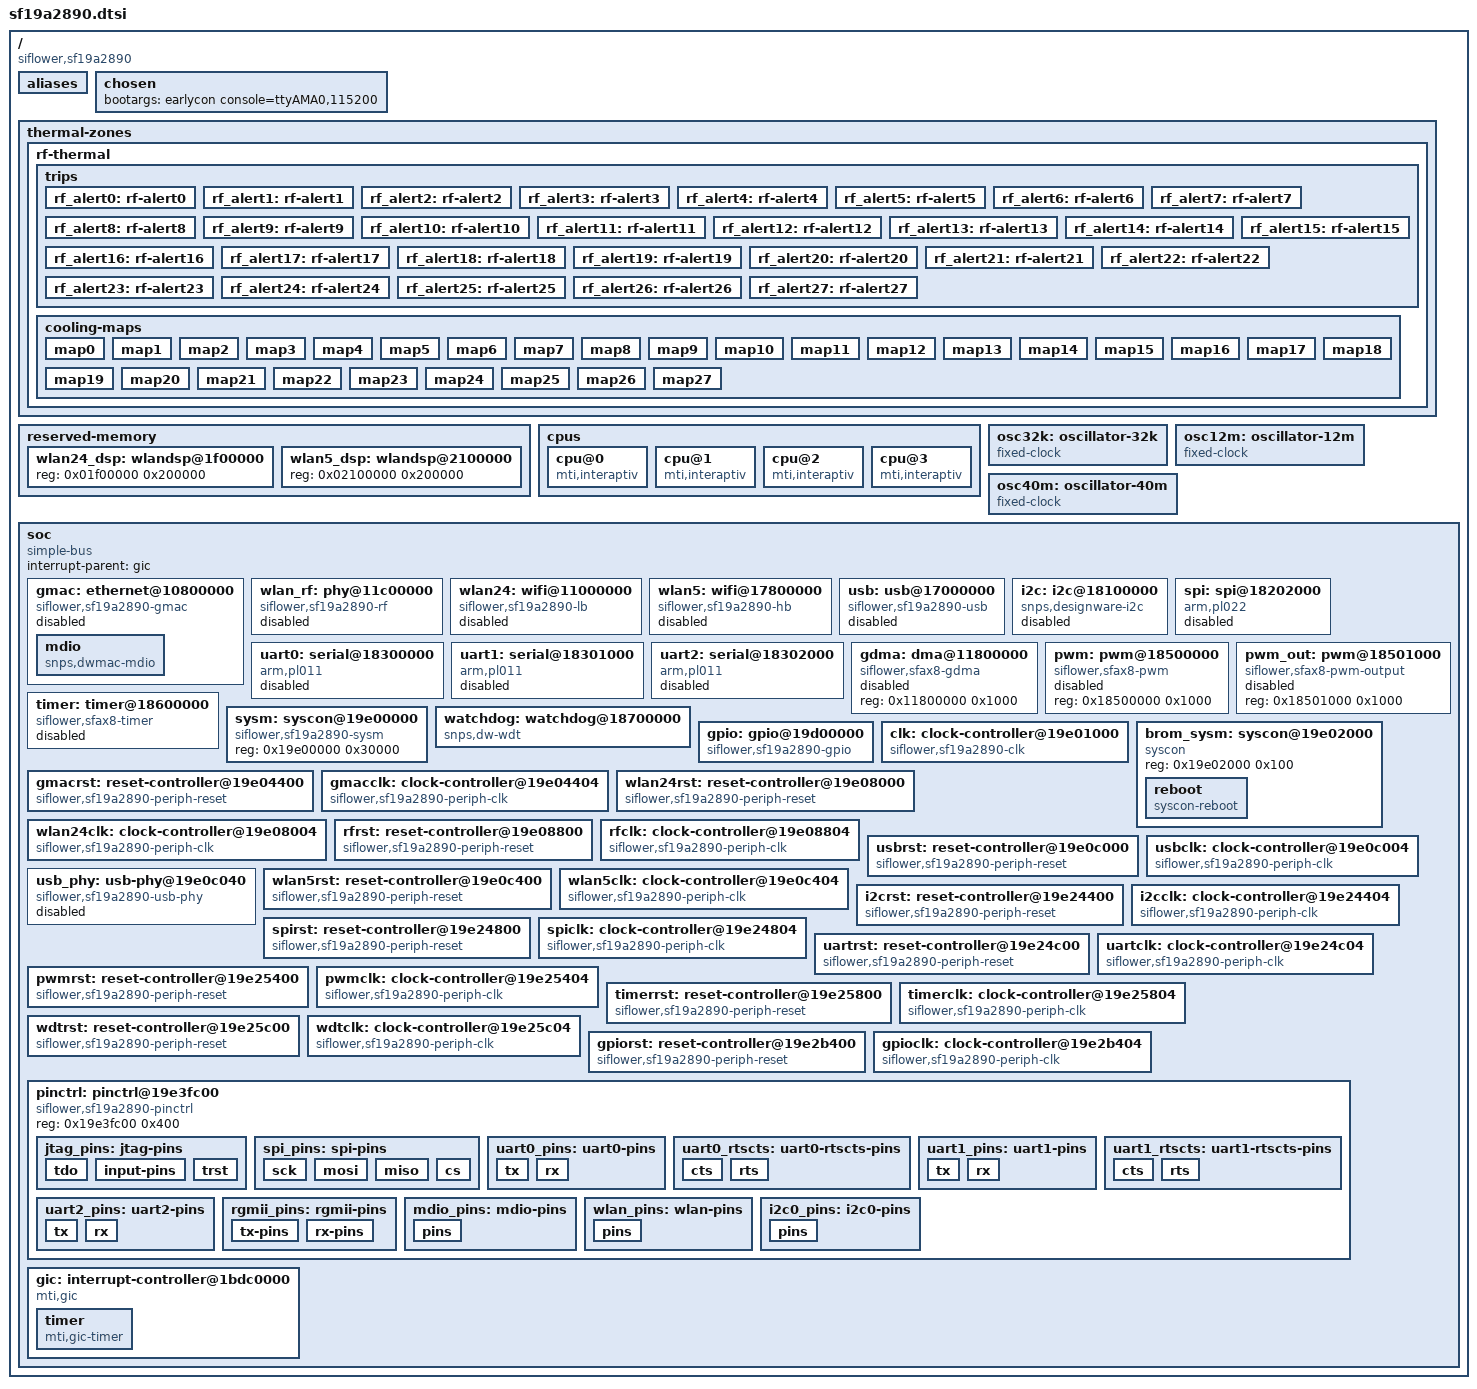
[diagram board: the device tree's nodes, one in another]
#include <dt-bindings/clock/siflower,sf19a2890-clk.h>
#include <dt-bindings/gpio/gpio.h>
#include <dt-bindings/interrupt-controller/irq.h>
#include <dt-bindings/interrupt-controller/mips-gic.h>

/ {
	compatible = "siflower,sf19a2890";
	#address-cells = <1>;
	#size-cells = <1>;


	aliases {
		serial0 = &uart0;
		serial1 = &uart1;
		serial2 = &uart2;
	};

	chosen {
		/*
		 * The vendor u-boot appends "console=ttyS0,115200n8" (and
		 * mem=/rdinit=) via MIPS_CMDLINE_DTB_EXTEND. A console=
		 * argument disables stdout-path based console selection,
		 * and ttyS0 does not exist (the UART is a PL011), which
		 * would leave the kernel silent after earlycon. Name the
		 * real console explicitly so it stays registered.
		 */
		bootargs = "earlycon console=ttyAMA0,115200";
	};

	thermal-zones {
		/*
		 * Mirrors the stock firmware rf_zone: the WiFi RF block is
		 * both the temperature sensor and the cooling device (TX
		 * power reduction), with 28 passive trips from -20C to 115C
		 * in 5C steps and the cooling state equal to the trip index.
		 */
		rf-thermal {
			polling-delay-passive = <1000>;
			polling-delay = <5000>;
			thermal-sensors = <&wlan_rf>;

			trips {
				rf_alert0: rf-alert0 {
					temperature = <(-20000)>;
					hysteresis = <1000>;
					type = "passive";
				};

				rf_alert1: rf-alert1 {
					temperature = <(-15000)>;
					hysteresis = <1000>;
					type = "passive";
				};

				rf_alert2: rf-alert2 {
					temperature = <(-10000)>;
					hysteresis = <1000>;
					type = "passive";
				};

				rf_alert3: rf-alert3 {
					temperature = <(-5000)>;
					hysteresis = <1000>;
					type = "passive";
				};

				rf_alert4: rf-alert4 {
					temperature = <0>;
					hysteresis = <1000>;
					type = "passive";
				};

				rf_alert5: rf-alert5 {
					temperature = <5000>;
					hysteresis = <1000>;
					type = "passive";
				};

				rf_alert6: rf-alert6 {
					temperature = <10000>;
					hysteresis = <1000>;
					type = "passive";
				};

				rf_alert7: rf-alert7 {
					temperature = <15000>;
					hysteresis = <1000>;
					type = "passive";
				};

				rf_alert8: rf-alert8 {
					temperature = <20000>;
					hysteresis = <1000>;
					type = "passive";
				};

				rf_alert9: rf-alert9 {
					temperature = <25000>;
					hysteresis = <1000>;
					type = "passive";
				};

				rf_alert10: rf-alert10 {
					temperature = <30000>;
					hysteresis = <1000>;
					type = "passive";
				};

				rf_alert11: rf-alert11 {
					temperature = <35000>;
					hysteresis = <1000>;
					type = "passive";
				};

				rf_alert12: rf-alert12 {
					temperature = <40000>;
					hysteresis = <1000>;
					type = "passive";
				};

				rf_alert13: rf-alert13 {
					temperature = <45000>;
					hysteresis = <1000>;
					type = "passive";
				};

				rf_alert14: rf-alert14 {
					temperature = <50000>;
					hysteresis = <1000>;
					type = "passive";
				};

				rf_alert15: rf-alert15 {
					temperature = <55000>;
					hysteresis = <1000>;
					type = "passive";
				};

				rf_alert16: rf-alert16 {
					temperature = <60000>;
					hysteresis = <1000>;
					type = "passive";
				};

				rf_alert17: rf-alert17 {
					temperature = <65000>;
					hysteresis = <1000>;
					type = "passive";
				};

				rf_alert18: rf-alert18 {
					temperature = <70000>;
					hysteresis = <1000>;
					type = "passive";
				};

				rf_alert19: rf-alert19 {
					temperature = <75000>;
					hysteresis = <1000>;
					type = "passive";
				};

				rf_alert20: rf-alert20 {
					temperature = <80000>;
					hysteresis = <1000>;
					type = "passive";
				};

				rf_alert21: rf-alert21 {
					temperature = <85000>;
					hysteresis = <1000>;
					type = "passive";
				};

				rf_alert22: rf-alert22 {
					temperature = <90000>;
					hysteresis = <1000>;
					type = "passive";
				};

				rf_alert23: rf-alert23 {
					temperature = <95000>;
					hysteresis = <1000>;
					type = "passive";
				};

				rf_alert24: rf-alert24 {
					temperature = <100000>;
					hysteresis = <1000>;
					type = "passive";
				};

				rf_alert25: rf-alert25 {
					temperature = <105000>;
					hysteresis = <1000>;
					type = "passive";
				};

				rf_alert26: rf-alert26 {
					temperature = <110000>;
					hysteresis = <1000>;
					type = "passive";
				};

				rf_alert27: rf-alert27 {
					temperature = <115000>;
					hysteresis = <1000>;
					type = "passive";
				};
			};

			cooling-maps {
				map0 {
					trip = <&rf_alert0>;
					cooling-device = <&wlan_rf 0 0>;
				};

				map1 {
					trip = <&rf_alert1>;
					cooling-device = <&wlan_rf 1 1>;
				};

				map2 {
					trip = <&rf_alert2>;
					cooling-device = <&wlan_rf 2 2>;
				};

				map3 {
					trip = <&rf_alert3>;
					cooling-device = <&wlan_rf 3 3>;
				};

				map4 {
					trip = <&rf_alert4>;
					cooling-device = <&wlan_rf 4 4>;
				};

				map5 {
					trip = <&rf_alert5>;
					cooling-device = <&wlan_rf 5 5>;
				};

				map6 {
					trip = <&rf_alert6>;
					cooling-device = <&wlan_rf 6 6>;
				};

				map7 {
					trip = <&rf_alert7>;
					cooling-device = <&wlan_rf 7 7>;
				};

				map8 {
					trip = <&rf_alert8>;
					cooling-device = <&wlan_rf 8 8>;
				};

				map9 {
					trip = <&rf_alert9>;
					cooling-device = <&wlan_rf 9 9>;
				};

				map10 {
					trip = <&rf_alert10>;
					cooling-device = <&wlan_rf 10 10>;
				};

				map11 {
					trip = <&rf_alert11>;
					cooling-device = <&wlan_rf 11 11>;
				};

				map12 {
					trip = <&rf_alert12>;
					cooling-device = <&wlan_rf 12 12>;
				};

				map13 {
					trip = <&rf_alert13>;
					cooling-device = <&wlan_rf 13 13>;
				};

				map14 {
					trip = <&rf_alert14>;
					cooling-device = <&wlan_rf 14 14>;
				};

				map15 {
					trip = <&rf_alert15>;
					cooling-device = <&wlan_rf 15 15>;
				};

				map16 {
					trip = <&rf_alert16>;
					cooling-device = <&wlan_rf 16 16>;
				};

				map17 {
					trip = <&rf_alert17>;
					cooling-device = <&wlan_rf 17 17>;
				};

				map18 {
					trip = <&rf_alert18>;
					cooling-device = <&wlan_rf 18 18>;
				};

				map19 {
					trip = <&rf_alert19>;
					cooling-device = <&wlan_rf 19 19>;
				};

				map20 {
					trip = <&rf_alert20>;
					cooling-device = <&wlan_rf 20 20>;
				};

				map21 {
					trip = <&rf_alert21>;
					cooling-device = <&wlan_rf 21 21>;
				};

				map22 {
					trip = <&rf_alert22>;
					cooling-device = <&wlan_rf 22 22>;
				};

				map23 {
					trip = <&rf_alert23>;
					cooling-device = <&wlan_rf 23 23>;
				};

				map24 {
					trip = <&rf_alert24>;
					cooling-device = <&wlan_rf 24 24>;
				};

				map25 {
					trip = <&rf_alert25>;
					cooling-device = <&wlan_rf 25 25>;
				};

				map26 {
					trip = <&rf_alert26>;
					cooling-device = <&wlan_rf 26 26>;
				};

				map27 {
					trip = <&rf_alert27>;
					cooling-device = <&wlan_rf 27 27>;
				};
			};
		};
	};

	reserved-memory {
		#address-cells = <1>;
		#size-cells = <1>;
		ranges;

		wlan24_dsp: wlandsp@1f00000 {
			reg = <0x01f00000 0x200000>;
		};

		wlan5_dsp: wlandsp@2100000 {
			reg = <0x02100000 0x200000>;
		};
	};

	cpus {
		#address-cells = <1>;
		#size-cells = <0>;

		cpu@0 {
			device_type = "cpu";
			compatible = "mti,interaptiv";
			reg = <0>;
			clocks = <&clk CLK_MUXDIV_CPU>;
			clock-names = "cpu";
			clock-latency = <0>;
		};

		cpu@1 {
			device_type = "cpu";
			compatible = "mti,interaptiv";
			reg = <1>;
			clocks = <&clk CLK_MUXDIV_CPU>;
			clock-names = "cpu";
			clock-latency = <0>;
		};
		cpu@2 {
			device_type = "cpu";
			compatible = "mti,interaptiv";
			reg = <2>;
			clocks = <&clk CLK_MUXDIV_CPU>;
			clock-names = "cpu";
			clock-latency = <0>;
		};
		cpu@3 {
			device_type = "cpu";
			compatible = "mti,interaptiv";
			reg = <3>;
			clocks = <&clk CLK_MUXDIV_CPU>;
			clock-names = "cpu";
			clock-latency = <0>;
		};
	};

	osc32k: oscillator-32k {
		compatible = "fixed-clock";
		clock-frequency = <32768>;
		#clock-cells = <0>;
		clock-output-names = "osc32k";
	};

	osc12m: oscillator-12m {
		compatible = "fixed-clock";
		clock-frequency = <12000000>;
		#clock-cells = <0>;
		clock-output-names = "osc12m";
	};

	osc40m: oscillator-40m {
		compatible = "fixed-clock";
		clock-frequency = <40000000>;
		#clock-cells = <0>;
		clock-output-names = "osc40m";
	};

	soc {
		#address-cells = <1>;
		#size-cells = <1>;
		compatible = "simple-bus";
		ranges;
		interrupt-parent = <&gic>;

		gmac: ethernet@10800000 {
			compatible = "siflower,sf19a2890-gmac", "snps,dwmac";
			reg = <0x10800000 0x200000>,
				<0x19e04440 0x10>;
			interrupts = <GIC_SHARED 32 IRQ_TYPE_LEVEL_HIGH>,
					<GIC_SHARED 34 IRQ_TYPE_LEVEL_HIGH>,
					<GIC_SHARED 33 IRQ_TYPE_LEVEL_HIGH>;
			interrupt-names = "macirq", "eth_wake_irq", "eth_lpi";
			clocks = <&gmacclk 0>, <&gmacclk 1>, <&gmacclk 3>, <&gmacclk 2>;
			clock-names = "stmmaceth", "pclk", "ptp_ref", "gmac_byp_ref";
			resets = <&gmacrst 0>;
			reset-names = "stmmaceth";
			pinctrl-names = "default";
			pinctrl-0 = <&rgmii_pins>, <&mdio_pins>;
			tx-fifo-depth = <2048>;
			rx-fifo-depth = <2048>;
			status = "disabled";

			mdio: mdio {
				compatible = "snps,dwmac-mdio";
				#address-cells = <1>;
				#size-cells = <0>;
			};
		};

		wlan_rf: phy@11c00000{
			compatible = "siflower,sf19a2890-rf";
			reg = <0x11c00000 0x600000>;
			interrupts = <GIC_SHARED 187 IRQ_TYPE_LEVEL_HIGH>;
			clocks = <&rfclk 1>, <&rfclk 2>, <&rfclk 3>;
			clock-names = "axi", "boot", "lp";
			resets = <&rfrst 0>;
			pinctrl-names = "default";
			pinctrl-0 = <&wlan_pins>;
			#thermal-sensor-cells = <0>;
			#cooling-cells = <2>;
			status = "disabled";
		};

		/* Register ranges match the vendor DT on stock firmware:
		 * LB MAC at 0x11000000, HB MAC at 0x17800000.
		 */
		wlan24: wifi@11000000 {
			compatible = "siflower,sf19a2890-lb";
			reg = <0x11000000 0x400000>;
			interrupts = <GIC_SHARED 176 IRQ_TYPE_LEVEL_HIGH>,
				     <GIC_SHARED 177 IRQ_TYPE_LEVEL_HIGH>;
			interrupt-names = "lmac", "umac";
			clocks = <&wlan24clk 0>, <&wlan24clk 1>, <&wlan24clk 2>,
				 <&clk CLK_MUXDIV_CPU>, <&clk CLK_MUXDIV_BUS2>,
				 <&clk CLK_MUXDIV_BUS3>, <&clk CLK_MUXDIV_PBUS>,
				 <&clk CLK_MUXDIV_WLAN24_PLF>;
			clock-names = "wlan_axis", "wlan_axim", "wlan_plf",
				      "clk_cpu", "clk_bus2", "clk_bus3",
				      "clk_pbus", "clk_wlan_plf";
			resets = <&wlan24rst 0>;
			reset-names = "wlan_reset";
			memory-region = <&wlan24_dsp>;
			status = "disabled";
		};

		wlan5: wifi@17800000 {
			compatible = "siflower,sf19a2890-hb";
			reg = <0x17800000 0x400000>;
			interrupts = <GIC_SHARED 178 IRQ_TYPE_LEVEL_HIGH>,
				     <GIC_SHARED 179 IRQ_TYPE_LEVEL_HIGH>;
			interrupt-names = "lmac", "umac";
			clocks = <&wlan5clk 0>, <&wlan5clk 1>, <&wlan5clk 2>,
				 <&clk CLK_MUXDIV_CPU>, <&clk CLK_MUXDIV_BUS2>,
				 <&clk CLK_MUXDIV_BUS3>, <&clk CLK_MUXDIV_PBUS>,
				 <&clk CLK_MUXDIV_WLAN5_PLF>;
			clock-names = "wlan_axis", "wlan_axim", "wlan_plf",
				      "clk_cpu", "clk_bus2", "clk_bus3",
				      "clk_pbus", "clk_wlan_plf";
			resets = <&wlan5rst 0>;
			reset-names = "wlan_reset";
			memory-region = <&wlan5_dsp>;
			status = "disabled";
		};

		usb: usb@17000000 {
			compatible = "siflower,sf19a2890-usb";
			reg = <0x17000000 0x40000>;
			interrupts = <GIC_SHARED 128 IRQ_TYPE_LEVEL_HIGH>;
			clocks = <&usbclk 0>;
			clock-names = "otg";
			resets = <&usbrst 0>;
			reset-names = "dwc2";
			dr_mode = "otg";
			phys = <&usb_phy>;
			phy-names = "usb2-phy";
			g-np-tx-fifo-size = <768>;
			status = "disabled";
		};

		i2c: i2c@18100000 {
			compatible = "snps,designware-i2c";
			reg = <0x18100000 0x1000>;
			#address-cells = <1>;
			#size-cells = <0>;
			interrupts = <GIC_SHARED 217 IRQ_TYPE_LEVEL_HIGH>;
			clocks = <&i2cclk 0>;
			clock-names = "ref";
			clock-frequency = <400000>;
			resets = <&i2crst 0>;
			pinctrl-names = "default";
			pinctrl-0 = <&i2c0_pins>;
			status = "disabled";
		};

		spi: spi@18202000 {
			compatible = "arm,pl022", "arm,primecell";
			reg = <0x18202000 0x1000>;
			cs-gpios = <&gpio 8 GPIO_ACTIVE_LOW>;
			clocks = <&spiclk 1>, <&spiclk 0>;
			clock-names = "sspclk", "apb_pclk";
			interrupts = <GIC_SHARED 225 IRQ_TYPE_LEVEL_HIGH>;
			resets = <&spirst 0>;
			#address-cells = <1>;
			#size-cells = <0>;
			pinctrl-names = "default";
			pinctrl-0 = <&spi_pins>;
			status = "disabled";
		};

		uart0: serial@18300000 {
			compatible = "arm,pl011", "arm,primecell";
			reg = <0x18300000 0x1000>;
			interrupts = <GIC_SHARED 226 IRQ_TYPE_LEVEL_HIGH>;
			clocks = <&uartclk 3>, <&uartclk 0>;
			clock-names = "uartclk", "apb_pclk";
			resets = <&uartrst 0>;
			pinctrl-names = "default";
			pinctrl-0 = <&uart0_pins>;
			status = "disabled";
		};

		uart1: serial@18301000 {
			compatible = "arm,pl011", "arm,primecell";
			reg = <0x18301000 0x1000>;
			interrupts = <GIC_SHARED 227 IRQ_TYPE_LEVEL_HIGH>;
			clocks = <&uartclk 4>, <&uartclk 1>;
			clock-names = "uartclk", "apb_pclk";
			resets = <&uartrst 1>;
			pinctrl-names = "default";
			pinctrl-0 = <&uart1_pins>;
			status = "disabled";
		};

		uart2: serial@18302000 {
			compatible = "arm,pl011", "arm,primecell";
			reg = <0x18302000 0x1000>;
			interrupts = <GIC_SHARED 228 IRQ_TYPE_LEVEL_HIGH>;
			clocks = <&uartclk 5>, <&uartclk 2>;
			clock-names = "uartclk", "apb_pclk";
			resets = <&uartrst 2>;
			pinctrl-names = "default";
			pinctrl-0 = <&uart2_pins>;
			status = "disabled";
		};

		gdma: dma@11800000 {
			compatible = "siflower,sfax8-gdma";
			reg = <0x11800000 0x1000>;
			status = "disabled";
		};

		pwm: pwm@18500000 {
			compatible = "siflower,sfax8-pwm";
			reg = <0x18500000 0x1000>;
			status = "disabled";
		};

		pwm_out: pwm@18501000 {
			compatible = "siflower,sfax8-pwm-output";
			reg = <0x18501000 0x1000>;
			status = "disabled";
		};

		timer: timer@18600000 {
			compatible = "siflower,sfax8-timer";
			reg = <0x18600000 0x14>, <0x18600014 0x14>,
			      <0x18601000 0x14>, <0x18601014 0x14>;
			status = "disabled";
		};

		sysm: syscon@19e00000 {
			compatible = "siflower,sf19a2890-sysm", "syscon";
			reg = <0x19e00000 0x30000>;
		};

		watchdog: watchdog@18700000 {
			compatible = "snps,dw-wdt";
			reg = <0x18700000 0x1000>;
			interrupts = <GIC_SHARED 238 IRQ_TYPE_LEVEL_HIGH>;
			clocks = <&wdtclk 0>;
			resets = <&wdtrst 0>;
		};

		gpio: gpio@19d00000 {
			compatible = "siflower,sf19a2890-gpio";
			reg=<0x19d00000 0x100000>;
			interrupts = <GIC_SHARED 246 IRQ_TYPE_LEVEL_HIGH>,
				     <GIC_SHARED 247 IRQ_TYPE_LEVEL_HIGH>,
				     <GIC_SHARED 248 IRQ_TYPE_LEVEL_HIGH>,
				     <GIC_SHARED 249 IRQ_TYPE_LEVEL_HIGH>;
			clocks = <&gpioclk 0>;
			resets = <&gpiorst 0>;

			gpio-controller;
			#gpio-cells = <2>;
			ngpios = <49>;
			gpio-ranges = <&pinctrl 0 0 49>;

			interrupt-controller;
			#interrupt-cells = <2>;
		};

		clk: clock-controller@19e01000 {
			compatible = "siflower,sf19a2890-clk";
			reg = <0x19e01000 0x800>;
			clocks = <&osc12m>, <&osc40m>;
			clock-names = "osc12m", "osc40m";
			#clock-cells = <1>;
		};

		brom_sysm: syscon@19e02000 {
			compatible = "syscon", "simple-mfd";
			reg = <0x19e02000 0x100>;

			reboot {
				compatible = "syscon-reboot";
				offset = <0x30>;
				value = <0x1>;
			};
		};

		gmacrst: reset-controller@19e04400 {
			compatible = "siflower,sf19a2890-periph-reset";
			reg = <0x19e04400 0x4>;
			#reset-cells = <1>;
			siflower,reset-masks = <0x3>;
		};

		gmacclk: clock-controller@19e04404 {
			compatible = "siflower,sf19a2890-periph-clk";
			reg = <0x19e04404 0xc>;
			clocks = <&clk CLK_MUXDIV_BUS1>, <&clk CLK_MUXDIV_CPU>, <&clk CLK_MUXDIV_GMAC_BYP_REF>, <&clk CLK_MUXDIV_ETH_TSU>;
			clock-output-names = "gmac", "gmac_pclk", "gmac_byp_ref", "ethtsu";
			#clock-cells = <1>;
		};

		wlan24rst: reset-controller@19e08000 {
			compatible = "siflower,sf19a2890-periph-reset";
			reg = <0x19e08000 0x4>;
			#reset-cells = <1>;
			siflower,reset-masks = <0x7>;
		};

		wlan24clk: clock-controller@19e08004 {
			compatible = "siflower,sf19a2890-periph-clk";
			reg = <0x19e08004 0xc>;
			clocks = <&clk CLK_MUXDIV_CPU>, <&clk CLK_MUXDIV_BUS2>, <&clk CLK_MUXDIV_WLAN24_PLF>;
			clock-output-names = "wlan24_axis", "wlan24_axim", "wlan24_plf";
			#clock-cells = <1>;
		};

		rfrst: reset-controller@19e08800 {
			compatible = "siflower,sf19a2890-periph-reset";
			reg = <0x19e08800 0x4>;
			#reset-cells = <1>;
			siflower,reset-masks = <0x7>;
		};

		rfclk: clock-controller@19e08804 {
			compatible = "siflower,sf19a2890-periph-clk";
			reg = <0x19e08804 0xc>;
			clocks = <&clk CLK_MUXDIV_BUS2>, <&clk CLK_MUXDIV_CPU>, <&osc12m>, <&osc32k>;
			clock-output-names = "rf_dft", "rf_axis", "rf_boot", "rf_lp";
			#clock-cells = <1>;
		};

		usbrst: reset-controller@19e0c000 {
			compatible = "siflower,sf19a2890-periph-reset";
			reg = <0x19e0c000 0x4>;
			#reset-cells = <1>;
			siflower,reset-masks = <0x7 0x8 0x10>;
		};

		usbclk: clock-controller@19e0c004 {
			compatible = "siflower,sf19a2890-periph-clk";
			reg = <0x19e0c004 0xc>;
			clocks = <&clk CLK_MUXDIV_BUS3>, <&clk CLK_MUXDIV_CPU>, <&clk CLK_MUXDIV_USBPHY_REF>;
			clock-output-names = "usb", "usb_axim", "usbphy_ref";
			siflower,valid-gates = <0xd>;
			siflower,critical-gates = <0x4>;
			#clock-cells = <1>;
		};

		usb_phy: usb-phy@19e0c040 {
			compatible = "siflower,sf19a2890-usb-phy";
			reg = <0x19e0C040 0x60>;
			clocks = <&usbclk 2>;
			resets = <&usbrst 1>, <&usbrst 2>;
			reset-names = "power_on_rst", "usb_phy_rst";
			#phy-cells = <0>;
			status = "disabled";
		};

		wlan5rst: reset-controller@19e0c400 {
			compatible = "siflower,sf19a2890-periph-reset";
			reg = <0x19e0c400 0x4>;
			#reset-cells = <1>;
			siflower,reset-masks = <0x7>;
		};

		wlan5clk: clock-controller@19e0c404 {
			compatible = "siflower,sf19a2890-periph-clk";
			reg = <0x19e0c404 0xc>;
			clocks = <&clk CLK_MUXDIV_CPU>, <&clk CLK_MUXDIV_BUS2>, <&clk CLK_MUXDIV_WLAN5_PLF>;
			clock-output-names = "wlan5_axis", "wlan5_axim", "wlan5_plf";
			#clock-cells = <1>;
		};

		i2crst: reset-controller@19e24400 {
			compatible = "siflower,sf19a2890-periph-reset";
			reg = <0x19e24400 0x4>;
			#reset-cells = <1>;
			siflower,num-resets = <1>;
		};

		i2cclk: clock-controller@19e24404 {
			compatible = "siflower,sf19a2890-periph-clk";
			reg = <0x19e24404 0xc>;
			clocks = <&clk CLK_MUXDIV_PBUS>;
			clock-output-names = "i2c0";
			#clock-cells = <1>;
		};

		spirst: reset-controller@19e24800 {
			compatible = "siflower,sf19a2890-periph-reset";
			reg = <0x19e24800 0x4>;
			#reset-cells = <1>;
			siflower,reset-masks = <0x30>;
		};

		spiclk: clock-controller@19e24804 {
			compatible = "siflower,sf19a2890-periph-clk";
			reg = <0x19e24804 0xc>;
			clocks = <&clk CLK_MUXDIV_PBUS>, <&clk CLK_MUXDIV_PBUS>;
			clock-output-names = "spi_apb", "spi_ssp";
			siflower,valid-gates = <0x30>;
			#clock-cells = <1>;
		};

		uartrst: reset-controller@19e24c00 {
			compatible = "siflower,sf19a2890-periph-reset";
			reg = <0x19e24c00 0x4>;
			#reset-cells = <1>;
			siflower,reset-masks = <0x11 0x22 0x44>;
		};

		uartclk: clock-controller@19e24c04 {
			compatible = "siflower,sf19a2890-periph-clk";
			reg = <0x19e24c04 0xc>;
			clocks = <&clk CLK_MUXDIV_PBUS>, <&clk CLK_MUXDIV_PBUS>, <&clk CLK_MUXDIV_PBUS>,
				 <&clk CLK_MUXDIV_UART>, <&clk CLK_MUXDIV_UART>, <&clk CLK_MUXDIV_UART>;
			clock-output-names = "uart0_apb", "uart1_apb", "uart2_apb",
					     "uart0", "uart1","uart2";
			siflower,valid-gates = <0x77>;
			siflower,critical-gates = <0x11>;
			#clock-cells = <1>;
		};

		pwmrst: reset-controller@19e25400 {
			compatible = "siflower,sf19a2890-periph-reset";
			reg = <0x19e25400 0x4>;
			#reset-cells = <1>;
			siflower,num-resets = <1>;
		};

		pwmclk: clock-controller@19e25404 {
			compatible = "siflower,sf19a2890-periph-clk";
			reg = <0x19e25404 0xc>;
			clocks = <&clk CLK_MUXDIV_PBUS>;
			clock-output-names = "pwm";
			#clock-cells = <1>;
		};

		timerrst: reset-controller@19e25800 {
			compatible = "siflower,sf19a2890-periph-reset";
			reg = <0x19e25800 0x4>;
			#reset-cells = <1>;
			siflower,num-resets = <1>;
		};

		timerclk: clock-controller@19e25804 {
			compatible = "siflower,sf19a2890-periph-clk";
			reg = <0x19e25804 0xc>;
			clocks = <&clk CLK_MUXDIV_PBUS>;
			clock-output-names = "timer";
			#clock-cells = <1>;
		};

		wdtrst: reset-controller@19e25c00 {
			compatible = "siflower,sf19a2890-periph-reset";
			reg = <0x19e25c00 0x4>;
			#reset-cells = <1>;
			siflower,num-resets = <1>;
		};

		wdtclk: clock-controller@19e25c04 {
			compatible = "siflower,sf19a2890-periph-clk";
			reg = <0x19e25c04 0xc>;
			clocks = <&clk CLK_MUXDIV_PBUS>;
			clock-output-names = "wdt";
			#clock-cells = <1>;
		};

		gpiorst: reset-controller@19e2b400 {
			compatible = "siflower,sf19a2890-periph-reset";
			reg = <0x19e2b400 0x4>;
			#reset-cells = <1>;
			siflower,num-resets = <1>;
		};

		gpioclk: clock-controller@19e2b404 {
			compatible = "siflower,sf19a2890-periph-clk";
			reg = <0x19e2b404 0xc>;
			clocks = <&clk CLK_MUXDIV_PBUS>;
			clock-output-names = "gpio";
			#clock-cells = <1>;
		};

		pinctrl: pinctrl@19e3fc00 {
			compatible = "siflower,sf19a2890-pinctrl";
			reg = <0x19e3fc00 0x400>;

			jtag_pins: jtag-pins {
				tdo {
					pins = "JTAG_TDO";
					function = "func0";
					bias-disable;
				};

				input-pins {
					pins = "JTAG_TDI", "JTAG_TMS", "JTAG_TCK";
					function = "func0";
					input-enable;
					bias-disable;
				};

				trst {
					pins = "JTAG_RST";
					function = "func0";
					input-enable;
					bias-pull-down;
				};
			};

			spi_pins: spi-pins {
				sck {
					pins = "SPI_CLK";
					function = "func0";
					bias-disable;
				};

				mosi {
					pins = "SPI_TXD";
					function = "func0";
					bias-pull-down;
				};

				miso {
					pins = "SPI_RXD";
					function = "func0";
					input-enable;
					bias-pull-down;
				};

				cs {
					pins = "SPI_CSN";
					bias-pull-up;
				};
			};

			uart0_pins: uart0-pins {
				tx {
					pins = "UART_TX";
					function = "func0";
					bias-pull-up;
				};

				rx {
					pins = "UART_RX";
					function = "func0";
					input-enable;
					bias-pull-up;
				};
			};

			uart0_rtscts: uart0-rtscts-pins {
				cts {
					pins = "I2C_DAT";
					function = "func0";
					input-enable;
					bias-pull-up;
				};

				rts {
					pins = "I2C_CLK";
					function = "func0";
					bias-pull-up;
				};
			};

			uart1_pins: uart1-pins {
				tx {
					pins = "JATG_TDO";
					function = "func1";
					bias-pull-up;
				};

				rx {
					pins = "JATG_TDI";
					function = "func1";
					input-enable;
					bias-pull-up;
				};
			};

			uart1_rtscts: uart1-rtscts-pins {
				cts {
					pins = "JTAG_TMS";
					function = "func1";
					input-enable;
					bias-pull-up;
				};

				rts {
					pins = "JTAG_TCK";
					function = "func1";
					bias-pull-up;
				};
			};

			uart2_pins: uart2-pins {
				tx {
					pins = "I2C_DAT";
					function = "func1";
					bias-pull-up;
				};

				rx {
					pins = "I2C_CLK";
					function = "func1";
					input-enable;
					bias-pull-up;
				};
			};

			rgmii_pins: rgmii-pins {
				tx-pins {
					pins =  "RGMII_TXCLK", "RGMII_TXD0",
						"RGMII_TXD1", "RGMII_TXD2",
						"RGMII_TXD3", "RGMII_TXCTL";
					function = "func0";
					bias-disable;
				};

				rx-pins {
					pins = "RGMII_RXCLK", "RGMII_RXD0",
						"RGMII_RXD1", "RGMII_RXD2",
						"RGMII_RXD3", "RGMII_RXCTL";
					function = "func0";
					input-enable;
					bias-disable;
				};
			};

			mdio_pins: mdio-pins {
				pins {
					pins = "RGMII_MDC", "RGMII_MDIO";
					function = "func0";
					input-enable;
					bias-pull-up;
				};
			};

			wlan_pins: wlan-pins {
				pins {
					pins = "HB0_PA_EN", "HB0_LNA_EN",
						"HB0_SW_CTRL0", "HB0_SW_CTRL1",
						"HB1_PA_EN", "HB1_LNA_EN",
						"HB1_SW_CTRL0", "HB1_SW_CTRL1",
						"LB0_PA_EN", "LB0_LNA_EN",
						"LB0_SW_CTRL0", "LB0_SW_CTRL1",
						"LB1_PA_EN", "LB1_LNA_EN",
						"LB1_SW_CTRL0", "LB1_SW_CTRL1";
					function = "func0";
				};
			};


			i2c0_pins: i2c0-pins {
				pins {
					pins = "I2C_CLK", "I2C_DAT";
					function = "func2";
					input-enable;
					bias-pull-up;
				};
			};
		};

		gic: interrupt-controller@1bdc0000 {
			compatible = "mti,gic";
			reg = <0x1bdc0000 0x20000>;
			interrupt-controller;
			#interrupt-cells = <3>;
			mti,reserved-ipi-vectors = <0 8>;

			timer {
				compatible = "mti,gic-timer";
				interrupts = <GIC_LOCAL 1 IRQ_TYPE_NONE>;
				clocks = <&clk CLK_MUXDIV_CPU>;
			};
		};
	};
};
